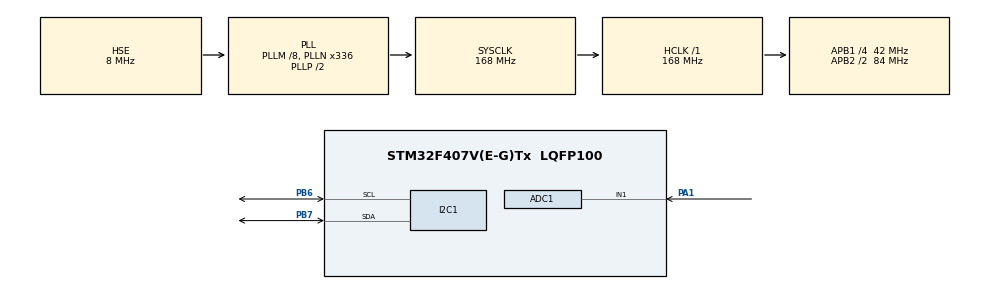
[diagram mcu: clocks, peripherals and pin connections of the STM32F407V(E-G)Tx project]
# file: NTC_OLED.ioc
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ADC1.Channel-0\#ChannelRegularConversion=ADC_CHANNEL_1
ADC1.NbrOfConversionFlag=1
ADC1.Rank-0\#ChannelRegularConversion=1
ADC1.SamplingTime-0\#ChannelRegularConversion=ADC_SAMPLETIME_3CYCLES
ADC1.master=1
I2C1.I2C_Mode=I2C_Fast
Mcu.Family=STM32F4
Mcu.Name=STM32F407V(E-G)Tx
Mcu.Package=LQFP100
NVIC.PriorityGroup=NVIC_PRIORITYGROUP_0
PA1.Signal=ADCx_IN1
PA13.Mode=Serial_Wire
PA13.Signal=SYS_JTMS-SWDIO
PA14.Mode=Serial_Wire
PA14.Signal=SYS_JTCK-SWCLK
PB6.Mode=I2C
PB6.Signal=I2C1_SCL
PB7.Mode=I2C
PB7.Signal=I2C1_SDA
PH0-OSC_IN.Mode=HSE-External-Oscillator
PH0-OSC_IN.Signal=RCC_OSC_IN
PH1-OSC_OUT.Mode=HSE-External-Oscillator
PH1-OSC_OUT.Signal=RCC_OSC_OUT
ProjectManager.HeapSize=0x200
ProjectManager.StackSize=0x400
ProjectManager.TargetToolchain=STM32CubeIDE
RCC.48MHZClocksFreq_Value=48000000
RCC.AHBFreq_Value=168000000
RCC.APB1CLKDivider=RCC_HCLK_DIV4
RCC.APB1Freq_Value=42000000
RCC.APB1TimFreq_Value=84000000
RCC.APB2CLKDivider=RCC_HCLK_DIV2
RCC.APB2Freq_Value=84000000
RCC.APB2TimFreq_Value=168000000
RCC.CortexFreq_Value=168000000
RCC.HCLKFreq_Value=168000000
RCC.HSE_VALUE=8000000
RCC.HSI_VALUE=16000000
RCC.PLLM=8
RCC.PLLN=336
RCC.PLLQ=7
RCC.PLLSourceVirtual=RCC_PLLSOURCE_HSE
RCC.SYSCLKFreq_VALUE=168000000
RCC.SYSCLKSource=RCC_SYSCLKSOURCE_PLLCLK
RCC.VCOOutputFreq_Value=336000000
SH.ADCx_IN1.0=ADC1_IN1,IN1
board=STM32F407G-DISC1

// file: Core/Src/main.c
/* USER CODE BEGIN Header */
/**
  ******************************************************************************
  * @file           : main.c
  * @brief          : Main program body
  ******************************************************************************
  * @attention
  *
  * Copyright (c) 2023 STMicroelectronics.
  * All rights reserved.
  *
  * This software is licensed under terms that can be found in the LICENSE file
  * in the root directory of this software component.
  * If no LICENSE file comes with this software, it is provided AS-IS.
  *
  ******************************************************************************
  */
/* USER CODE END Header */
#include "main.h"
#include "stdio.h"
#include "math.h"

/* USER CODE BEGIN Includes */
#include "ssd1306.h"
#include "fonts.h"
#include "test.h"

/* USER CODE END Includes */

ADC_HandleTypeDef hadc1;

I2C_HandleTypeDef hi2c1;

/* USER CODE BEGIN PV */
uint16_t adcValue=0;
uint16_t temperature=0;
char string[25];

/* USER CODE END PV */

void SystemClock_Config(void);
static void MX_GPIO_Init(void);
static void MX_I2C1_Init(void);
static void MX_ADC1_Init(void);

/* USER CODE BEGIN 0 */
uint16_t adcRead(){
	HAL_ADC_Start(&hadc1);
	 if(HAL_ADC_PollForConversion(&hadc1, 100)==HAL_OK){
		 adcValue=HAL_ADC_GetValue(&hadc1);
	 }
	 HAL_ADC_Stop(&hadc1);
	 return adcValue;
}
double fhToCn(uint16_t adcValue){
	double temp=0;
	temp=log(((40950000/adcValue)-10000));
	temp=1/(0.001129148 +(0.000234125  +(0.0000000876741*temp*temp))*temp);
	temp=temp-273.15;
	return temp;

}

/* USER CODE END 0 */

int main(void)
{

  /* MCU Configuration--------------------------------------------------------*/

  /* Reset of all peripherals, Initializes the Flash interface and the Systick. */
  HAL_Init();

  /* Configure the system clock */
  SystemClock_Config();

  /* Initialize all configured peripherals */
  MX_GPIO_Init();
  MX_I2C1_Init();
  MX_ADC1_Init();
  /* USER CODE BEGIN 2 */
  SSD1306_Init();

  /* USER CODE END 2 */

  /* Infinite loop */
  while (1)
  {

    /* USER CODE BEGIN 3 */
	  adcValue=adcRead();
	  temperature=fhToCn(adcValue);
	  HAL_Delay(300);
	  SSD1306_Clear();
	  SSD1306_GotoXY(20, 0);//kordinat
	  SSD1306_Puts("Sicaklik",&Font_11x18,1);
	  SSD1306_DrawLine(0, 20, 128, 20, 1);
	  SSD1306_GotoXY(30, 28);
	  itoa(temperature,string,10);
	  SSD1306_Puts(string,&Font_11x18, 1);
	  SSD1306_GotoXY(60, 28);
	  SSD1306_Puts("C",&Font_11x18, 1);
	  SSD1306_DrawLine(0, 48, 128, 48, 1);

	  SSD1306_GotoXY(0, 50);
	  SSD1306_Puts("Omer Faruk Yavuz",&Font_7x10, 1);

	  SSD1306_UpdateScreen();
	  HAL_Delay(1000);
  }
  /* USER CODE END 3 */
}

void SystemClock_Config(void)
{
  RCC_OscInitTypeDef RCC_OscInitStruct = {0};
  RCC_ClkInitTypeDef RCC_ClkInitStruct = {0};

  /** Configure the main internal regulator output voltage
  */
  __HAL_RCC_PWR_CLK_ENABLE();
  __HAL_PWR_VOLTAGESCALING_CONFIG(PWR_REGULATOR_VOLTAGE_SCALE1);

  /** Initializes the RCC Oscillators according to the specified parameters
  * in the RCC_OscInitTypeDef structure.
  */
  RCC_OscInitStruct.OscillatorType = RCC_OSCILLATORTYPE_HSE;
  RCC_OscInitStruct.HSEState = RCC_HSE_ON;
  RCC_OscInitStruct.PLL.PLLState = RCC_PLL_ON;
  RCC_OscInitStruct.PLL.PLLSource = RCC_PLLSOURCE_HSE;
  RCC_OscInitStruct.PLL.PLLM = 8;
  RCC_OscInitStruct.PLL.PLLN = 336;
  RCC_OscInitStruct.PLL.PLLP = RCC_PLLP_DIV2;
  RCC_OscInitStruct.PLL.PLLQ = 7;
  if (HAL_RCC_OscConfig(&RCC_OscInitStruct) != HAL_OK)
  {
    Error_Handler();
  }

  /** Initializes the CPU, AHB and APB buses clocks
  */
  RCC_ClkInitStruct.ClockType = RCC_CLOCKTYPE_HCLK|RCC_CLOCKTYPE_SYSCLK
                              |RCC_CLOCKTYPE_PCLK1|RCC_CLOCKTYPE_PCLK2;
  RCC_ClkInitStruct.SYSCLKSource = RCC_SYSCLKSOURCE_PLLCLK;
  RCC_ClkInitStruct.AHBCLKDivider = RCC_SYSCLK_DIV1;
  RCC_ClkInitStruct.APB1CLKDivider = RCC_HCLK_DIV4;
  RCC_ClkInitStruct.APB2CLKDivider = RCC_HCLK_DIV2;

  if (HAL_RCC_ClockConfig(&RCC_ClkInitStruct, FLASH_LATENCY_5) != HAL_OK)
  {
    Error_Handler();
  }
}

static void MX_ADC1_Init(void)
{

  ADC_ChannelConfTypeDef sConfig = {0};

  /** Configure the global features of the ADC (Clock, Resolution, Data Alignment and number of conversion)
  */
  hadc1.Instance = ADC1;
  hadc1.Init.ClockPrescaler = ADC_CLOCK_SYNC_PCLK_DIV4;
  hadc1.Init.Resolution = ADC_RESOLUTION_12B;
  hadc1.Init.ScanConvMode = DISABLE;
  hadc1.Init.ContinuousConvMode = DISABLE;
  hadc1.Init.DiscontinuousConvMode = DISABLE;
  hadc1.Init.ExternalTrigConvEdge = ADC_EXTERNALTRIGCONVEDGE_NONE;
  hadc1.Init.ExternalTrigConv = ADC_SOFTWARE_START;
  hadc1.Init.DataAlign = ADC_DATAALIGN_RIGHT;
  hadc1.Init.NbrOfConversion = 1;
  hadc1.Init.DMAContinuousRequests = DISABLE;
  hadc1.Init.EOCSelection = ADC_EOC_SINGLE_CONV;
  if (HAL_ADC_Init(&hadc1) != HAL_OK)
  {
    Error_Handler();
  }

  /** Configure for the selected ADC regular channel its corresponding rank in the sequencer and its sample time.
  */
  sConfig.Channel = ADC_CHANNEL_1;
  sConfig.Rank = 1;
  sConfig.SamplingTime = ADC_SAMPLETIME_3CYCLES;
  if (HAL_ADC_ConfigChannel(&hadc1, &sConfig) != HAL_OK)
  {
    Error_Handler();
  }

}

static void MX_I2C1_Init(void)
{

  hi2c1.Instance = I2C1;
  hi2c1.Init.ClockSpeed = 400000;
  hi2c1.Init.DutyCycle = I2C_DUTYCYCLE_2;
  hi2c1.Init.OwnAddress1 = 0;
  hi2c1.Init.AddressingMode = I2C_ADDRESSINGMODE_7BIT;
  hi2c1.Init.DualAddressMode = I2C_DUALADDRESS_DISABLE;
  hi2c1.Init.OwnAddress2 = 0;
  hi2c1.Init.GeneralCallMode = I2C_GENERALCALL_DISABLE;
  hi2c1.Init.NoStretchMode = I2C_NOSTRETCH_DISABLE;
  if (HAL_I2C_Init(&hi2c1) != HAL_OK)
  {
    Error_Handler();
  }

}

static void MX_GPIO_Init(void)
{

  /* GPIO Ports Clock Enable */
  __HAL_RCC_GPIOH_CLK_ENABLE();
  __HAL_RCC_GPIOA_CLK_ENABLE();
  __HAL_RCC_GPIOB_CLK_ENABLE();

}

void Error_Handler(void)
{
  __disable_irq();
  while (1)
  {
  }
}
